# STM32MP13xx register map
File version: 1.5
CPU: CA7 r0p0, little endian, MPU, FPU, 4 interrupt priority bits
Registers are 32-bit, read-write, reset 0x0 unless marked. A register's access mark holds for its fields unless they carry their own. Offsets are from the block's base; [hi:lo] are bit positions; {n}, {i} and the like mark numbered series.

## PWR
Base 0x50001000
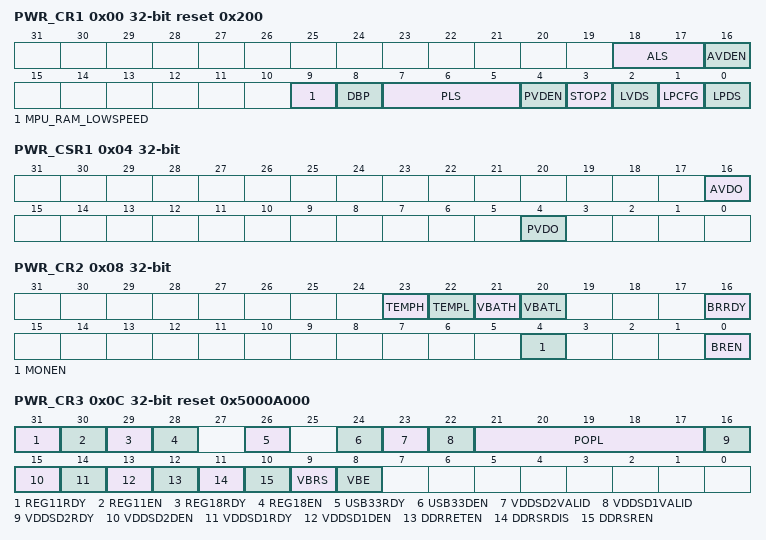
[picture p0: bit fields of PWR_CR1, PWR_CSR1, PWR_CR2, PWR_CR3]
0x00 PWR_CR1 reset 0x200 — PWR control register 1
  [18:17] ALS — Analog Voltage Detector level selection. These bits select the voltage threshold detected by the AVD.
    0=1.7V; 1=2.1V; 2=2.5V; 3=2.8V
  [16] AVDEN — Peripheral Voltage Monitor on VDDA enable.
    0=Peripheral Voltage Monitor on VDDA disabled; 1=Peripheral Voltage Monitor on VDDA enabled
  [9] MPU_RAM_LOWSPEED — Low speed selection for MPU memories This bit must be reset by software when MPU needs to operate in Overdrive (High speed) mode It must be set after decreasing the MPU frequency to operate in standard frequency range.
    0=MPU can operate in High speed mode (VDDCPU > 1.2V); 1=MPU can only operate in Low speed mode (VDDCPU â¤ 1.2 V)
  [8] DBP — Disable backup domain write protection. In reset state, the RCC_BDCR, PWR_CR2, RTC, and backup registers are protected against parasitic write access. This bit must be set to enable write access to these.
    0=Write access to RTC and backup domain registers disabled; 1=Write access to RTC and backup domain registers enabled
  [7:5] PLS — Programmable Voltage Detector level selection. These bits are read only when the SYSCFG register bit PVDL is set (when PVDL is set, there is no bus errors generated when writing this register). These bits select the voltage threshold detected by the PVD.
    0=1.95 V; 1=2.1 V; 2=2.25 V; 3=2.4 V; 4=2.55 V; 5=2.7 V; 6=2.85 V; 7=External voltage level on PVD_IN (compared to internal VREFINT)
  [4] PVDEN — Programmable Voltage detector enable. This bit is read only when the SYSCFG register bit PVDL is set (when PVDL is set, there is no bus errors generated when writing this register).
    0=Programmable Voltage detector disabled; 1=Programmable Voltage detector enabled
  [3] STOP2 — System LPLV-Stop2 mode selection
    0=Keeps System Stop mode when PDDS=0 and MPU enters CStop; 1=Allows System LPLV-Stop2 mode when PDDS = 0
  [2] LVDS — Low Voltage Deepsleep LPLV-Stop mode selection. This bit has only effect when the low power stop mode is selected in LPDS and changes the VDDCORE and VDDCPU domains supply reset level.
    0=LP-Stop mode VDDCORE and VDDCPU domains supply reset level at same level as Run mode. The VDDCORE and VDDCPU domains supply level in LP-Stop mode must be kept at same level as Run mode.; 1=LPLV-Stop mode VDDCORE and VDDCPU domains supply reset level at lower level than Run mode. Allows to lower VDDCORE and VDDCPU domains supply level in LPLV-Stop mode (see the datasheet for voltage levels).
  [1] LPCFG — PWR_ON pin configuration.
    0=PWR_ON pin signals Standby mode (PWR_ON =1 in Run, Stop, LP-Stop, LPLV-Stop, LPLV-Stop2 and 0 in Standby); 1=PWR_ON pin signals Standby, LP-Stop, LPLV-Stop and LPLV-Stop2 modes (PWR_ON = 1 in Run, Stop, and 0 in LP-Stop, LPLV-Stop, LPLV-Stop2 and Standby)
  [0] LPDS — Low Power Deepsleep Stop mode selection.
    0=Stop mode selected, External regulator kept in Main power mode (pwr_lp = 1); 1=low-power stop mode selected External regulator may enter Low-power mode (pwr_lp = 0). Further low power mode selection is provided by LVDS.
0x04 PWR_CSR1 ro — PWR control status register 1
  [16] AVDO — Analog Voltage detector Output on VDDA. This bit is set and cleared by hardware. It is valid only if AVD on VDDA is enabled by the AVDEN bit. Note: The AVD is disabled in Standby mode and after system reset. For this reason, this bit is equal to 0 after Standby and reset.
    0=VDDA is equal or higher than the AVD threshold selected with the ALS[2:0] bits; 1=VDDA is lower than the AVD threshold selected with the ALS[2:0] bits
  [4] PVDO — Programmable Voltage Detect Output This bit is set and cleared by hardware. It is valid only if PVD is enabled by the PVDEN bit. Note: The PVD is disabled in Standby mode and after a system reset. For this reason, this bit is equal to 0 after Standby and system reset.
    0=VDD or voltage level on PVD_IN is equal or higher than the PVD threshold selected with the PLS[2:0] bits; 1=VDD or voltage level on PVD_IN is lower than the PVD threshold selected with the PLS[2:0] bits
0x08 PWR_CR2 access per field — PWR control register 2
  [23] TEMPH ro — Monitored temperature level above high threshold
    0=Temperature below high threshold level, or Monitor disabled; 1=Temperature equal or above high threshold level
  [22] TEMPL ro — Monitored temperature level above low threshold
    0=Temperature above low threshold level, or Monitor disabled; 1=Temperature equal or below low threshold level
  [21] VBATH ro — Monitored VBAT level above high threshold
    0=VBAT level below high threshold level, or Monitor disabled; 1=VBAT level equal or above high threshold level
  [20] VBATL ro — Monitored VBAT level above low threshold
    0=VBAT level above low threshold level, or Monitor disabled; 1=VBAT level equal or below low threshold level
  [16] BRRDY ro — Backup Regulator ready Set by hardware to indicate that the Backup Regulator is ready. Entering Standby or VBAT mode before the Backup Regulator is ready may cause loss of Backup RAM content.
    0=Backup Regulator not ready; 1=Backup Regulator ready
  [4] MONEN rw — VBAT and temperature monitoring enable When set, the VBAT supply and temperature monitoring is enabled.
    0=VBAT and temperature monitoring disabled; 1=VBAT and temperature monitoring enabled
  [0] BREN rw — Backup regulator enable When set, the backup regulator (used to maintain backup RAM content in Standby and VBAT modes) is enabled. If BREN is reset, the backup regulator is switched off. The backup RAM can still be used in Run mode and Stop mode but its content is lost in the Standby and VBAT modes. Once set, the application must wait that the Backup Regulator Ready flag (BRRDY) is set to indicate that the data written into the SRAM is maintained in the Standby and VBAT modes.
    0=Backup regulator disabled; 1=Backup regulator enabled
0x0C PWR_CR3 access per field reset 0x5000A000 — PWR control register 3
  [31] REG11RDY ro — 1V1 regulator supply ready
    0=1V1 supply not ready; 1=1V1 supply ready
  [30] REG11EN rw — 1V1 regulator enable
    0=1V1 regulator disabled; 1=1V1 regulator enabled (when in Standby mode the 1V1 regulator is disabled)
  [29] REG18RDY ro — 1V8 regulator supply ready
    0=1V8 supply not ready; 1=1V8 supply ready
  [28] REG18EN rw — 1V8 regulator enable
    0=1V8 regulator disabled; 1=1V8 regulator enabled, when also pin BYPASS_REG1V8 is low (when in Standby mode the 1V8 regulator is disabled)
  [26] USB33RDY ro — USB 3.3V supply ready
    0=USB 3.3V supply not ready; 1=USB 3.3V supply ready
  [24] USB33DEN rw — USB 3.3V voltage level detector enable
    0=USB 3.3V voltage level detector; 1=USB 3.3V voltage level detector
  [23] VDDSD2VALID rw — Override VDDSD2 voltage detector This bit enables the I/Os in the VDDSD2 domain whatever the state of VDDSD2RDY. This bit can be set by software once VDDSD2 is higher than VDDSDx_TH and stable (bit VDDSD2RDYÂ =Â 1). Subsequently VDDSD2EN can be reset to 0 to disable the voltage detector and save power (refer to datasheet for VDDSDx_TH value).
    0=I/O enable/disable is controlled by the VDDSD2 voltage detector; 1=I/O enable is forced active
  [22] VDDSD1VALID rw — Override VDDSD1 voltage detector This bit enables the I/Os in the VDDSD1 domain whatever the state of VDDSD1RDY. This bit can be set by software once VDDSD1 is higher than VDDSDx_TH and stable (bit VDDSD1RDYÂ =Â 1). Subsequently VDDSD1EN can be reset to 0 to disable the voltage detector and save power (refer to datasheet for VDDSDx_TH value).
    0=I/O enable/disable is controlled by the VDDSD1 voltage detector; 1=I/O enable is forced active
  [21:17] POPL rw — PWR_ON, PWR_CPU_ON Standby pulse low configuration These bits are set and cleared by software. They define the minimum guaranteed duration of the PWR_ON and PWR_CPU_ON low pulse in Standby mode (there is no impact on the LP-Stop and LPLV-Stop modes). The LSI oscillator is automatically enabled when needed by the POPL pulse low configuration. ...
    0=~ 62.5 us guaranteed minimum low time (2 LSI cycles); 1=~ 1 ms guaranteed minimum low time (1 x 32 LSI cycles); 2=~ 2 ms guaranteed minimum low time (2 x 32 LSI cycles); 31=~ 31 ms guaranteed minimum low time (31 x 32 LSI cycles)
  [16] VDDSD2RDY ro — VDDSD2 supply ready When the level detector is active (VDDSD2DEN = 1), this bit indicates if a voltage higher than VDDSDx_TH is present on the VDDSD2 supply (refer to datasheet for VDDSDx_TH value).
    0=VDDSD2 supply not present, or voltage detector switched off (VDDSD2EN = 0); 1=VDDSD2 supply present
  [15] VDDSD2DEN rw — VDDSD2 voltage level detector enable The voltage level detector is active by default. It enables the I/Os in the VDDSD2 domain if and when the VDDSD2 supply voltage is higher than VDDSDx_TH. Once the supply is stable above this threshold (VDDSD2RDYÂ =Â 1), the level detectors can be switched off to save power, without disabling the I/Os, by setting VDDSD2VALIDÂ =Â 1 followed by VDDSD2ENÂ =Â 0 (refer to datasheet for VDDSDx_TH value).
    0=VDDSD2 level detector switched off. I/Os in VDDSD2 domain are also disabled if VDDSD2VALIDÂ =Â 0; 1=VDDSD2 level detector is active. I/Os in VDDSD2 domain are active if VDDSD2RDY = 1
  [14] VDDSD1RDY ro — VDDSD1 supply ready When the level detector is active (VDDSD1DEN = 1), this bit indicates if a voltage higher than VDDSDx_TH is present on the VDDSD1 supply (refer to datasheet for VDDSDx_TH value).
    0=VDDSD1 supply not present, or voltage detector switched off (VDDSD1EN = 0); 1=VDDSD1 supply present
  [13] VDDSD1DEN rw — VDDSD1 voltage level detector enable The voltage level detector is active by default. It enables the I/Os in the VDDSD1 domain if and when the VDDSD1 supply voltage is higher than VDDSDx_TH. Once the supply is stable above this threshold (VDDSD1RDYÂ =Â 1), the level detectors can be switched off to save power, without disabling the I/Os, by setting VDDSD1VALIDÂ =Â 1 followed by VDDSD1ENÂ =Â 0 (refer to datasheet for VDDSDx_TH value).
    0=VDDSD1 level detector switched off. I/Os in VDDSD1 domain are also disabled if VDDSD1VALIDÂ =Â 0; 1=VDDSD1 level detector is active. I/Os in VDDSD1 domain are active if VDDSD1RDY = 1
  [12] DDRRETEN rw — DDR retention enable Set by Hardware on NRST pad reset, when the reset delay control is enabled in the RCC_MP_APRSTCR.RDCTLEN register bit, or when written 'b1 by software, the DDR PHY puts its pads in retention. To disable retention software must write this bit to 'b0.
    0=DDR self-refresh retention disabled; 1=DDR self-refresh retention enabled
  [11] DDRSRDIS rw — DDR self-refresh retention after standby disable When written 'b1, the DDR PHY pads retention, enabled due to DDRSREN, is disabled.
    0=No action; 1=When DDRSREN is 'b1: Disable DDR self-refresh retention after standby mode. This bit is reset by hardware once DDR self-refresh retention has been disabled. When DRRSREN is 'b0 no action.
  [10] DDRSREN rw — DDR self-refresh in standby mode enable When set, the DDR PHY puts its pads in retention when entering Standby mode.
    0=DDR self-refresh retention when entering standby mode disabled; 1=DDR self-refresh retention when entering standby mode enabled (DDR self-refresh retention after Standby must be disabled by DDRSRDIS)
  [9] VBRS rw — VBAT charging resistor selection
    0=Charges VBAT through a 5 kOhm resistor; 1=Charges VBAT through a 1.5 kOhm resistor
  [8] VBE rw — VBAT charging enable
    0=VBAT battery charging disabled; 1=VBAT battery charging enabled
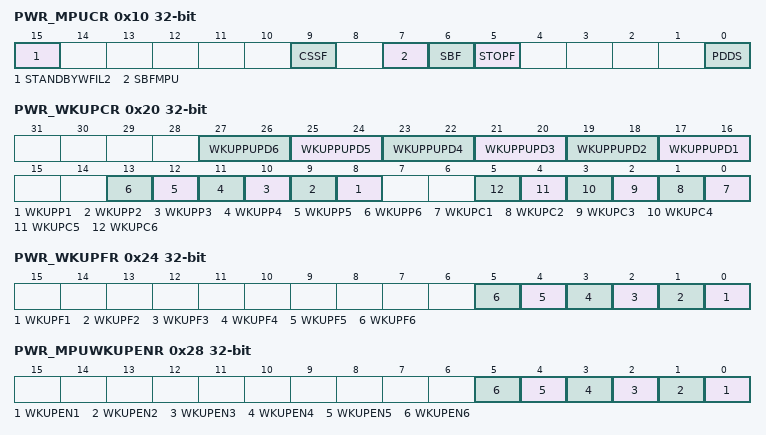
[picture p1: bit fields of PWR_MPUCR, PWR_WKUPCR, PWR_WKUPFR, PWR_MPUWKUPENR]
0x10 PWR_MPUCR access per field — PWR MPU control register
  [15] STANDBYWFIL2 ro — MPU system idle indication This bit is set and reset by hardware based on the MPU operation mode.
    0=MPU system CRun or CSleep; 1=MPU system CStop or CStandby
  [9] CSSF rw — Clear MPU Standby, Stop flags.(Always read as 0) This bit is reset on any system reset.
    0=No effect; 1=When written, clears the MPU flags (STOPF, SBF, and SBFMPU). The register bit is cleared to 0 by hardware.
  [7] SBFMPU ro — MPU Standby flag This bit is set by hardware and cleared only by a VDD POR reset or by setting the MPU CSSF bit (not reset when exit from Standby mode). This bit is cleared by the MPU Boot ROM. For more information refer to Boot ROM application note.
    0=MPU has not been in CStandby mode; 1=MPU has been in CStandby mode
  [6] SBF ro — System Standby flag This bit is set by hardware and cleared only by a VDD POR reset or by setting the MPU CSSF bit (not reset when exit from Standby mode). This bit is cleared by the MPU Boot ROM. For more information refer to Boot ROM application note.
    0=System has not been in Standby mode; 1=System has been in Standby mode, system contents has been lost
  [5] STOPF ro — Stop flag This bit is set by hardware and cleared only by any system reset or by setting the MPU CSSF bit. This bit is cleared by the MPU Boot ROM. For more information refer to Boot ROM application note.
    0=System has not been in Stop mode; 1=System has been in Stop mode, clock system has been stopped
  [0] PDDS rw — System Power Down Deepsleep selection This bit is reset only by a VDD POR reset (not reset when exit from Standby mode). Allows to define the Deepsleep mode for the system.
    0=Keeps System Stop when MPU enters to CStop or System LPLV-Stop2 mode when MPU enters to CStandby; 1=Allows System Standby mode when MPU enters to CStandby
0x20 PWR_WKUPCR — PWR wakeup control register
  [2n+15:2n+14] WKUPPUPD{n} (n=1..6) — Wakeup pull configuration for WKUPn pin (n = 6 to 1) These bits define the IO pad pull configuration used when WKUPENn = 1 (note that the associated GPIO port pull configuration must be set to the same value or 00). The wakeup pin pull configuration is maintained in Standby mode. When TZEN is enabled in the RCC and WKUPENn in (PWR_MPUWKUPENR) is set, bit pair n can only be written by a secure access, a non-secure write on this bit pair is discarded. When TZEN is disabled in the RCC or WKUPENn in (PWR_MPUWKUPENR) is clear, bit pair n can be written by a secure and non-secure access.
    0=No pulls; 1=Pull-up; 2=Pull-down
  [n+7] WKUPP{n} (n=1..6) — Wakeup Polarity bit for WKUPn pin, n range [6:1] These bits define the polarity used for event detection on external wake-up WKUPn pin. When TZEN is enabled in the RCC and WKUPENn in (PWR_MPUWKUPENR) is set, bit n can only be written by a secure access, a non-secure write on this bit is discarded. When TZEN is disabled in the RCC or WKUPENn in (PWR_MPUWKUPENR) is clear, bit n can be written by a secure and non-secure access.
    0=Detection on high level (rising edge); 1=Detection on low level (falling edge)
  [n-1] WKUPC{n} (n=1..6) — Clear Wakeup Flag for WKUPn pin, n range [6:1] When TZEN is enabled in the RCC and WKUPENn in (PWR_MPUWKUPENR) is set, bit n can only be written by a secure access, a non-secure write on this bit is discarded. When TZEN is disabled in the RCC or WKUPENn in (PWR_MPUWKUPENR) is clear, bit n can be written by a secure and non-secure access. These bits are always read as 0.
    0=No effect; 1=Writing 1 clears the WKUPFn wakeup flag (the bit is cleared to 0 by hardware)
0x24 PWR_WKUPFR ro — PWR wakeup flag register
  [all] fields
    0=No wakeup event occurred; 1=A wakeup event was received from WKUPCn pin
  [n-1] WKUPF{n} (n=1..6) — Wakeup flag for WKUPn pin before enable, n range [6:1]. This bit is set by hardware and cleared only by a NRST Reset or by setting the WKUPCn bit in the
0x28 PWR_MPUWKUPENR — PWR MPU wakeup enable register
  [all] fields
    0=An event on WKUPn pin does not wake up the system from Standby and Stop mode, nor generates an interrupt to MPU; 1=A rising or falling edge on WKUPn pin wakes up the system from Standby and Stop mode and generates an interrupt to MPU
  [n-1] WKUPEN{n} (n=1..6) — Enable Wakeup WKUPn pin and interrupt for MPU, n range [6:1] Each bit is set and cleared by software. When TZEN is enabled in the RCC, these bits can only be written by a secure access, a non-secure write is discarded. When TZEN is disabled in the RCC, these bits can be written by a secure and non-secure access.
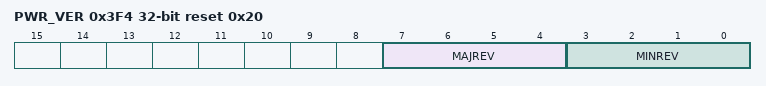
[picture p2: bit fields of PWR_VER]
0x3F4 PWR_VER ro reset 0x20 — PWR IP version register
  [7:4] MAJREV — Major revision number
  [3:0] MINREV — Minor revision number
0x3F8 PWR_ID ro reset 0x10001 — PWR IP identification register
  [31:0] IPID — IP identification
0x3FC PWR_SID ro reset 0xA3C5DD01 — PWR size ID register
  [31:0] SID — Size identification
